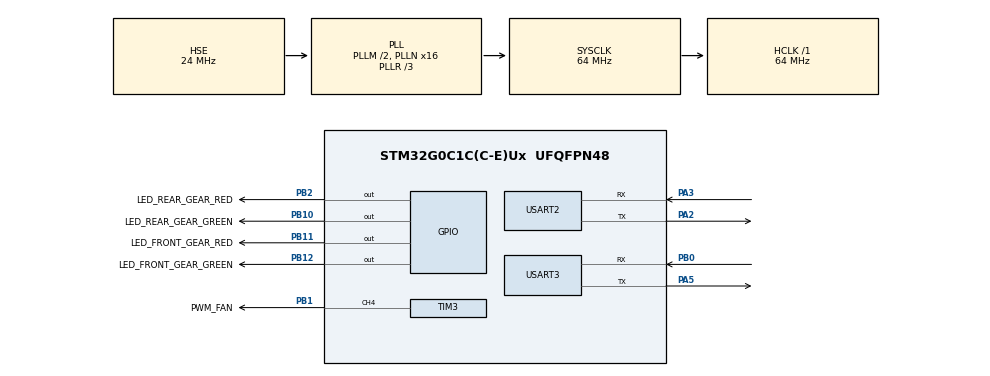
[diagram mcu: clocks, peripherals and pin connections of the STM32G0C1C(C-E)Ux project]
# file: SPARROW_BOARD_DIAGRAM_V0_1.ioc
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Mcu.Family=STM32G0
Mcu.Name=STM32G0C1C(C-E)Ux
Mcu.Package=UFQFPN48
NVIC.USART2_LPUART2_IRQn=true\:0\:0\:false\:false\:true\:true\:true\:true
NVIC.USART3_4_5_6_LPUART1_IRQn=true\:0\:0\:false\:false\:true\:true\:true\:true
PA13.Mode=Serial_Wire
PA13.Signal=SYS_SWDIO
PA14-BOOT0.Mode=Serial_Wire
PA14-BOOT0.Signal=SYS_SWCLK
PA2.Mode=Asynchronous
PA2.Signal=USART2_TX
PA3.GPIO_PuPd=GPIO_PULLUP
PA3.Mode=Asynchronous
PA3.Signal=USART2_RX
PA5.Mode=Asynchronous
PA5.Signal=USART3_TX
PB0.GPIO_PuPd=GPIO_PULLUP
PB0.Mode=Asynchronous
PB0.Signal=USART3_RX
PB1.GPIO_Label=PWM_FAN
PB1.Signal=S_TIM3_CH4
PB10.GPIO_Label=LED_REAR_GEAR_GREEN
PB10.GPIO_PuPd=GPIO_PULLDOWN
PB10.Signal=GPIO_Output
PB11.GPIO_Label=LED_FRONT_GEAR_RED
PB11.GPIO_PuPd=GPIO_PULLDOWN
PB11.Signal=GPIO_Output
PB12.GPIO_Label=LED_FRONT_GEAR_GREEN
PB12.GPIO_PuPd=GPIO_PULLDOWN
PB12.Signal=GPIO_Output
PB2.GPIO_Label=LED_REAR_GEAR_RED
PB2.GPIO_PuPd=GPIO_PULLDOWN
PB2.Signal=GPIO_Output
PF0-OSC_IN\ (PF0).Mode=HSE-External-Oscillator
PF0-OSC_IN\ (PF0).Signal=RCC_OSC_IN
PF1-OSC_OUT\ (PF1).Mode=HSE-External-Oscillator
PF1-OSC_OUT\ (PF1).Signal=RCC_OSC_OUT
ProjectManager.HeapSize=0x200
ProjectManager.StackSize=0x400
ProjectManager.TargetToolchain=STM32CubeIDE
RCC.ADCFreq_Value=64000000
RCC.AHBFreq_Value=64000000
RCC.CortexFreq_Value=64000000
RCC.EXTERNAL_CLOCK_VALUE=48000
RCC.HCLKFreq_Value=64000000
RCC.HSE_VALUE=24000000
RCC.HSI48_VALUE=48000000
RCC.HSI_VALUE=16000000
RCC.LSE_VALUE=32768
RCC.PLLM=RCC_PLLM_DIV2
RCC.PLLN=16
RCC.PLLR=RCC_PLLR_DIV3
RCC.PLLSourceVirtual=RCC_PLLSOURCE_HSE
RCC.SYSCLKFreq_VALUE=64000000
RCC.SYSCLKSource=RCC_SYSCLKSOURCE_PLLCLK
RCC.USBFreq_Value=48000000
RCC.VCOOutputFreq_Value=192000000
SH.S_TIM3_CH4.0=TIM3_CH4,PWM Generation4 CH4
TIM3.Channel-PWM\ Generation4\ CH4=TIM_CHANNEL_4
TIM3.Period=100
TIM3.Prescaler=63
USART2.VirtualMode-Asynchronous=VM_ASYNC
USART3.VirtualMode-Asynchronous=VM_ASYNC
VP_SYS_VS_DBSignals.Mode=DisableDeadBatterySignals
board=custom

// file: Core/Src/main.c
/* USER CODE BEGIN Header */
/**
  ******************************************************************************
  * @file           : main.c
  * @brief          : Main program body
  ******************************************************************************
  * @attention
  *
  * Copyright (c) 2025 STMicroelectronics.
  * All rights reserved.
  *
  * This software is licensed under terms that can be found in the LICENSE file
  * in the root directory of this software component.
  * If no LICENSE file comes with this software, it is provided AS-IS.
  *
  ******************************************************************************
  */
/* USER CODE END Header */
#include "main.h"

/* USER CODE BEGIN Includes */
#include "led_controller.h"

#include "fan_controller.h"
/* USER CODE END Includes */

TIM_HandleTypeDef htim3;

UART_HandleTypeDef huart2;
UART_HandleTypeDef huart3;

void SystemClock_Config(void);
static void MX_GPIO_Init(void);
static void MX_TIM3_Init(void);
static void MX_USART2_UART_Init(void);
static void MX_USART3_UART_Init(void);

int main(void)
{

  /* MCU Configuration--------------------------------------------------------*/

  /* Reset of all peripherals, Initializes the Flash interface and the Systick. */
  HAL_Init();

  /* Configure the system clock */
  SystemClock_Config();

  /* Initialize all configured peripherals */
  MX_GPIO_Init();
  MX_TIM3_Init();
  MX_USART2_UART_Init();
  MX_USART3_UART_Init();
  /* USER CODE BEGIN 2 */
  led_controller_init(GPIOB);
  fan_controller_init(&htim3);
  /* USER CODE END 2 */

  /* Infinite loop */
  /* USER CODE BEGIN WHILE */
  while (1)
  {
	  led_process();
	  static uint32_t last_read_tobufi = 0;
	  if(HAL_GetTick() - last_read_tobufi > 100)
	  {
		  fan_controller_process();
		  last_read_tobufi = HAL_GetTick();
	  }

    /* USER CODE END WHILE */

  }
}

void SystemClock_Config(void)
{
  RCC_OscInitTypeDef RCC_OscInitStruct = {0};
  RCC_ClkInitTypeDef RCC_ClkInitStruct = {0};

  /** Configure the main internal regulator output voltage
  */
  HAL_PWREx_ControlVoltageScaling(PWR_REGULATOR_VOLTAGE_SCALE1);

  /** Initializes the RCC Oscillators according to the specified parameters
  * in the RCC_OscInitTypeDef structure.
  */
  RCC_OscInitStruct.OscillatorType = RCC_OSCILLATORTYPE_HSE;
  RCC_OscInitStruct.HSEState = RCC_HSE_ON;
  RCC_OscInitStruct.PLL.PLLState = RCC_PLL_ON;
  RCC_OscInitStruct.PLL.PLLSource = RCC_PLLSOURCE_HSE;
  RCC_OscInitStruct.PLL.PLLM = RCC_PLLM_DIV2;
  RCC_OscInitStruct.PLL.PLLN = 16;
  RCC_OscInitStruct.PLL.PLLP = RCC_PLLP_DIV2;
  RCC_OscInitStruct.PLL.PLLQ = RCC_PLLQ_DIV2;
  RCC_OscInitStruct.PLL.PLLR = RCC_PLLR_DIV3;
  if (HAL_RCC_OscConfig(&RCC_OscInitStruct) != HAL_OK)
  {
    Error_Handler();
  }

  /** Initializes the CPU, AHB and APB buses clocks
  */
  RCC_ClkInitStruct.ClockType = RCC_CLOCKTYPE_HCLK|RCC_CLOCKTYPE_SYSCLK
                              |RCC_CLOCKTYPE_PCLK1;
  RCC_ClkInitStruct.SYSCLKSource = RCC_SYSCLKSOURCE_PLLCLK;
  RCC_ClkInitStruct.AHBCLKDivider = RCC_SYSCLK_DIV1;
  RCC_ClkInitStruct.APB1CLKDivider = RCC_HCLK_DIV1;

  if (HAL_RCC_ClockConfig(&RCC_ClkInitStruct, FLASH_LATENCY_2) != HAL_OK)
  {
    Error_Handler();
  }
}

static void MX_TIM3_Init(void)
{

  TIM_MasterConfigTypeDef sMasterConfig = {0};
  TIM_OC_InitTypeDef sConfigOC = {0};

  htim3.Instance = TIM3;
  htim3.Init.Prescaler = 63;
  htim3.Init.CounterMode = TIM_COUNTERMODE_UP;
  htim3.Init.Period = 100;
  htim3.Init.ClockDivision = TIM_CLOCKDIVISION_DIV1;
  htim3.Init.AutoReloadPreload = TIM_AUTORELOAD_PRELOAD_DISABLE;
  if (HAL_TIM_PWM_Init(&htim3) != HAL_OK)
  {
    Error_Handler();
  }
  sMasterConfig.MasterOutputTrigger = TIM_TRGO_RESET;
  sMasterConfig.MasterSlaveMode = TIM_MASTERSLAVEMODE_DISABLE;
  if (HAL_TIMEx_MasterConfigSynchronization(&htim3, &sMasterConfig) != HAL_OK)
  {
    Error_Handler();
  }
  sConfigOC.OCMode = TIM_OCMODE_PWM1;
  sConfigOC.Pulse = 0;
  sConfigOC.OCPolarity = TIM_OCPOLARITY_HIGH;
  sConfigOC.OCFastMode = TIM_OCFAST_DISABLE;
  if (HAL_TIM_PWM_ConfigChannel(&htim3, &sConfigOC, TIM_CHANNEL_4) != HAL_OK)
  {
    Error_Handler();
  }
  HAL_TIM_MspPostInit(&htim3);

}

static void MX_USART2_UART_Init(void)
{

  huart2.Instance = USART2;
  huart2.Init.BaudRate = 115200;
  huart2.Init.WordLength = UART_WORDLENGTH_8B;
  huart2.Init.StopBits = UART_STOPBITS_1;
  huart2.Init.Parity = UART_PARITY_NONE;
  huart2.Init.Mode = UART_MODE_TX_RX;
  huart2.Init.HwFlowCtl = UART_HWCONTROL_NONE;
  huart2.Init.OverSampling = UART_OVERSAMPLING_16;
  huart2.Init.OneBitSampling = UART_ONE_BIT_SAMPLE_DISABLE;
  huart2.Init.ClockPrescaler = UART_PRESCALER_DIV1;
  huart2.AdvancedInit.AdvFeatureInit = UART_ADVFEATURE_NO_INIT;
  if (HAL_UART_Init(&huart2) != HAL_OK)
  {
    Error_Handler();
  }
  if (HAL_UARTEx_SetTxFifoThreshold(&huart2, UART_TXFIFO_THRESHOLD_1_8) != HAL_OK)
  {
    Error_Handler();
  }
  if (HAL_UARTEx_SetRxFifoThreshold(&huart2, UART_RXFIFO_THRESHOLD_1_8) != HAL_OK)
  {
    Error_Handler();
  }
  if (HAL_UARTEx_DisableFifoMode(&huart2) != HAL_OK)
  {
    Error_Handler();
  }

}

static void MX_USART3_UART_Init(void)
{

  huart3.Instance = USART3;
  huart3.Init.BaudRate = 115200;
  huart3.Init.WordLength = UART_WORDLENGTH_8B;
  huart3.Init.StopBits = UART_STOPBITS_1;
  huart3.Init.Parity = UART_PARITY_NONE;
  huart3.Init.Mode = UART_MODE_TX_RX;
  huart3.Init.HwFlowCtl = UART_HWCONTROL_NONE;
  huart3.Init.OverSampling = UART_OVERSAMPLING_16;
  huart3.Init.OneBitSampling = UART_ONE_BIT_SAMPLE_DISABLE;
  huart3.Init.ClockPrescaler = UART_PRESCALER_DIV1;
  huart3.AdvancedInit.AdvFeatureInit = UART_ADVFEATURE_NO_INIT;
  if (HAL_UART_Init(&huart3) != HAL_OK)
  {
    Error_Handler();
  }
  if (HAL_UARTEx_SetTxFifoThreshold(&huart3, UART_TXFIFO_THRESHOLD_1_8) != HAL_OK)
  {
    Error_Handler();
  }
  if (HAL_UARTEx_SetRxFifoThreshold(&huart3, UART_RXFIFO_THRESHOLD_1_8) != HAL_OK)
  {
    Error_Handler();
  }
  if (HAL_UARTEx_DisableFifoMode(&huart3) != HAL_OK)
  {
    Error_Handler();
  }

}

static void MX_GPIO_Init(void)
{
  GPIO_InitTypeDef GPIO_InitStruct = {0};

  /* GPIO Ports Clock Enable */
  __HAL_RCC_GPIOF_CLK_ENABLE();
  __HAL_RCC_GPIOA_CLK_ENABLE();
  __HAL_RCC_GPIOB_CLK_ENABLE();

  /*Configure GPIO pin Output Level */
  HAL_GPIO_WritePin(GPIOB, LED_REAR_GEAR_RED_Pin|LED_REAR_GEAR_GREEN_Pin|LED_FRONT_GEAR_RED_Pin|LED_FRONT_GEAR_GREEN_Pin, GPIO_PIN_RESET);

  /*Configure GPIO pins : LED_REAR_GEAR_RED_Pin LED_REAR_GEAR_GREEN_Pin LED_FRONT_GEAR_RED_Pin LED_FRONT_GEAR_GREEN_Pin */
  GPIO_InitStruct.Pin = LED_REAR_GEAR_RED_Pin|LED_REAR_GEAR_GREEN_Pin|LED_FRONT_GEAR_RED_Pin|LED_FRONT_GEAR_GREEN_Pin;
  GPIO_InitStruct.Mode = GPIO_MODE_OUTPUT_PP;
  GPIO_InitStruct.Pull = GPIO_PULLDOWN;
  GPIO_InitStruct.Speed = GPIO_SPEED_FREQ_LOW;
  HAL_GPIO_Init(GPIOB, &GPIO_InitStruct);

}

void Error_Handler(void)
{
  __disable_irq();
  while (1)
  {
  }
}
